VERSION "HIPBNYYYYYYYYYYYYYYYYYYYYYYYYYYYYYYYYYYYYY/4/%%%/4/'%**4YYY///"

NS_ :

BS_:

BU_:

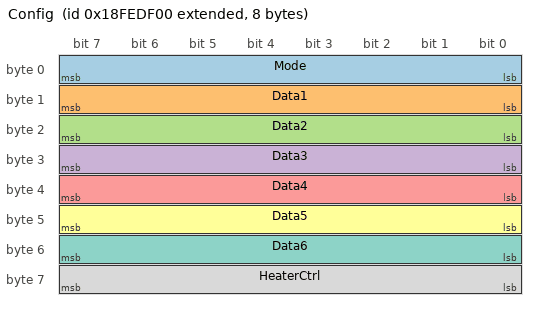
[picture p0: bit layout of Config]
BO_ 2566840064 Config: 8 Vector__XXX
 SG_ Mode : 7|8@0+ (1,0) [0|0] "" Vector__XXX
 SG_ Data1 : 8|8@1+ (1,0) [0|0] "" Vector__XXX
 SG_ Data2 : 16|8@1+ (1,0) [0|0] "" Vector__XXX
 SG_ Data3 : 24|8@1+ (1,0) [0|0] "" Vector__XXX
 SG_ Data4 : 32|8@1+ (1,0) [0|0] "" Vector__XXX
 SG_ Data5 : 40|8@1+ (1,0) [0|0] "" Vector__XXX
 SG_ Data6 : 48|8@1+ (1,0) [0|0] "" Vector__XXX
 SG_ HeaterCtrl : 63|8@0+ (1,0) [0|0] "" Vector__XXX

BO_ 1120 Sensor1: 8 Vector__XXX
 SG_ sw_ver1 m1 : 63|8@0+ (1,0) [0|0] "" Vector__XXX
 SG_ StatB71 m1 : 55|8@0+ (1,0) [0|0] "" Vector__XXX
 SG_ StatB61 m1 : 47|8@0+ (1,0) [0|0] "" Vector__XXX
 SG_ StatB51 m1 : 39|8@0+ (1,0) [0|0] "" Vector__XXX
 SG_ StatB41 m1 : 31|8@0+ (1,0) [0|0] "" Vector__XXX
 SG_ StatB31 m1 : 23|8@0+ (1,0) [0|0] "" Vector__XXX
 SG_ LSUState1 m1 : 15|8@0+ (1,0) [0|0] "" Vector__XXX
 SG_ Fault1 m0 : 55|8@0+ (1,0) [0|0] "" Vector__XXX
 SG_ PumpCurrent1 m0 : 31|16@0+ (1,32753) [0|0] "A" Vector__XXX
 SG_ Lambda1 m0 : 15|16@0+ (0.001,0) [0|0] "" Vector__XXX
 SG_ HeaterPWM1 m0 : 63|8@0+ (1,0) [0|0] "" Vector__XXX
 SG_ Mux1 M : 7|8@0+ (1,0) [0|0] "" Vector__XXX

BO_ 1121 Sensor2: 8 Vector__XXX
 SG_ sw_ver2 m1 : 63|8@0+ (1,0) [0|0] "" Vector__XXX
 SG_ Fault2 m0 : 55|8@0+ (1,0) [0|0] "" Vector__XXX
 SG_ StatB72 m1 : 55|8@0+ (1,0) [0|0] "" Vector__XXX
 SG_ StatB62 m1 : 47|8@0+ (1,0) [0|0] "" Vector__XXX
 SG_ StatB52 m1 : 39|8@0+ (1,0) [0|0] "" Vector__XXX
 SG_ StatB42 m1 : 31|8@0+ (1,0) [0|0] "" Vector__XXX
 SG_ StatB32 m1 : 23|8@0+ (1,0) [0|0] "" Vector__XXX
 SG_ PumpCurrent2 m0 : 31|16@0- (6E-006,0) [0|0] "A" Vector__XXX
 SG_ LSUState2 m1 : 15|8@0+ (1,0) [0|0] "" Vector__XXX
 SG_ Lambda2 m0 : 15|16@0+ (0.001,0) [0|0] "" Vector__XXX
 SG_ HeaterPWM2 m0 : 63|8@0+ (1,0) [0|0] "" Vector__XXX
 SG_ Mux2 M : 7|8@0+ (1,0) [0|0] "" Vector__XXX
